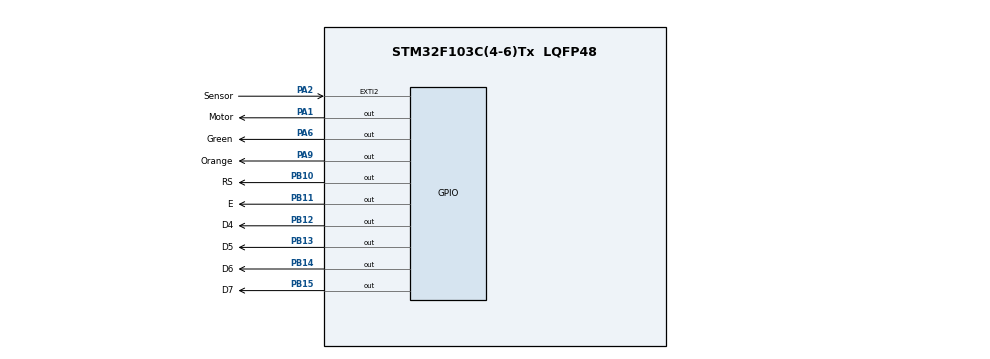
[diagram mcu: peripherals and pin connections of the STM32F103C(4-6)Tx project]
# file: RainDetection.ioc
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Mcu.Family=STM32F1
Mcu.Name=STM32F103C(4-6)Tx
Mcu.Package=LQFP48
NVIC.EXTI2_IRQn=true\:0\:0\:false\:false\:true\:true\:true\:true
NVIC.PriorityGroup=NVIC_PRIORITYGROUP_4
PA1.GPIO_Label=Motor
PA1.Signal=GPIO_Output
PA2.GPIO_Label=Sensor
PA2.Signal=GPXTI2
PA6.GPIO_Label=Green
PA6.Signal=GPIO_Output
PA9.GPIO_Label=Orange
PA9.Signal=GPIO_Output
PB10.GPIO_Label=RS
PB10.Signal=GPIO_Output
PB11.GPIO_Label=E
PB11.Signal=GPIO_Output
PB12.GPIO_Label=D4
PB12.Signal=GPIO_Output
PB13.GPIO_Label=D5
PB13.Signal=GPIO_Output
PB14.GPIO_Label=D6
PB14.Signal=GPIO_Output
PB15.GPIO_Label=D7
PB15.Signal=GPIO_Output
PD0-OSC_IN.Mode=HSE-External-Oscillator
PD0-OSC_IN.Signal=RCC_OSC_IN
PD1-OSC_OUT.Mode=HSE-External-Oscillator
PD1-OSC_OUT.Signal=RCC_OSC_OUT
ProjectManager.HeapSize=0x200
ProjectManager.StackSize=0x400
ProjectManager.TargetToolchain=MDK-ARM V5.32
RCC.APB1Freq_Value=8000000
RCC.APB2Freq_Value=8000000
VP_SYS_VS_ND.Mode=No_Debug
VP_TIM2_VS_ClockSourceINT.Mode=Internal
board=custom

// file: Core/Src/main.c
/* USER CODE BEGIN Header */
/**
  ******************************************************************************
  * @file           : main.c
  * @brief          : Main program body
  ******************************************************************************
  * @attention
  *
  * Copyright (c) 2023 STMicroelectronics.
  * All rights reserved.
  *
  * This software is licensed under terms that can be found in the LICENSE file
  * in the root directory of this software component.
  * If no LICENSE file comes with this software, it is provided AS-IS.
  *
  ******************************************************************************
  */
/* USER CODE END Header */
#include "main.h"
#include "stdio.h"
#include "lcd_txt.h"

TIM_HandleTypeDef htim2;

void SystemClock_Config(void);
static void MX_GPIO_Init(void);
static void MX_TIM2_Init(void);

int main(void)
{

  /* MCU Configuration--------------------------------------------------------*/

  /* Reset of all peripherals, Initializes the Flash interface and the Systick. */
  HAL_Init();

  /* Configure the system clock */
  SystemClock_Config();

  /* Initialize all configured peripherals */
  MX_GPIO_Init();
  MX_TIM2_Init();
  /* USER CODE BEGIN 2 */
	lcd_init();
  /* USER CODE END 2 */

  /* Infinite loop */
  /* USER CODE BEGIN WHILE */
  while (1)
  {

		if (HAL_GPIO_ReadPin(GPIOA, GPIO_PIN_2)) // if the pin is HIGH
		{
			HAL_GPIO_WritePin(GPIOA, GPIO_PIN_1, 0);
			lcd_puts(0, 0, (int8_t*)"RAIN DETECTED: Y");
			lcd_puts(1, 0, (int8_t*)"ROOF CLOSING:  Y");
			//HAL_GPIO_WritePin(GPIOA, GPIO_PIN_9, 1);
			//HAL_GPIO_WritePin(GPIOA, GPIO_PIN_6, GPIO_PIN_RESET);
		}
		else if(!HAL_GPIO_ReadPin(GPIOA, GPIO_PIN_2)){
			HAL_GPIO_WritePin(GPIOA, GPIO_PIN_1, 1);
			lcd_puts(0, 0, (int8_t*)"RAIN DETECTED: N");
			lcd_puts(1, 0, (int8_t*)"ROOF CLOSING:  N");
			//HAL_GPIO_WritePin(GPIOA, GPIO_PIN_6, 1);
			// HAL_GPIO_WritePin(GPIOA, GPIO_PIN_9, GPIO_PIN_RESET);

		}

    /* USER CODE END WHILE */

  }
}

void SystemClock_Config(void)
{
  RCC_OscInitTypeDef RCC_OscInitStruct = {0};
  RCC_ClkInitTypeDef RCC_ClkInitStruct = {0};

  /** Initializes the RCC Oscillators according to the specified parameters
  * in the RCC_OscInitTypeDef structure.
  */
  RCC_OscInitStruct.OscillatorType = RCC_OSCILLATORTYPE_HSI;
  RCC_OscInitStruct.HSIState = RCC_HSI_ON;
  RCC_OscInitStruct.HSICalibrationValue = RCC_HSICALIBRATION_DEFAULT;
  RCC_OscInitStruct.PLL.PLLState = RCC_PLL_NONE;
  if (HAL_RCC_OscConfig(&RCC_OscInitStruct) != HAL_OK)
  {
    Error_Handler();
  }

  /** Initializes the CPU, AHB and APB buses clocks
  */
  RCC_ClkInitStruct.ClockType = RCC_CLOCKTYPE_HCLK|RCC_CLOCKTYPE_SYSCLK
                              |RCC_CLOCKTYPE_PCLK1|RCC_CLOCKTYPE_PCLK2;
  RCC_ClkInitStruct.SYSCLKSource = RCC_SYSCLKSOURCE_HSI;
  RCC_ClkInitStruct.AHBCLKDivider = RCC_SYSCLK_DIV1;
  RCC_ClkInitStruct.APB1CLKDivider = RCC_HCLK_DIV1;
  RCC_ClkInitStruct.APB2CLKDivider = RCC_HCLK_DIV1;

  if (HAL_RCC_ClockConfig(&RCC_ClkInitStruct, FLASH_LATENCY_0) != HAL_OK)
  {
    Error_Handler();
  }
}

static void MX_TIM2_Init(void)
{

  TIM_ClockConfigTypeDef sClockSourceConfig = {0};
  TIM_MasterConfigTypeDef sMasterConfig = {0};

  htim2.Instance = TIM2;
  htim2.Init.Prescaler = 0;
  htim2.Init.CounterMode = TIM_COUNTERMODE_UP;
  htim2.Init.Period = 65535;
  htim2.Init.ClockDivision = TIM_CLOCKDIVISION_DIV1;
  htim2.Init.AutoReloadPreload = TIM_AUTORELOAD_PRELOAD_DISABLE;
  if (HAL_TIM_Base_Init(&htim2) != HAL_OK)
  {
    Error_Handler();
  }
  sClockSourceConfig.ClockSource = TIM_CLOCKSOURCE_INTERNAL;
  if (HAL_TIM_ConfigClockSource(&htim2, &sClockSourceConfig) != HAL_OK)
  {
    Error_Handler();
  }
  sMasterConfig.MasterOutputTrigger = TIM_TRGO_RESET;
  sMasterConfig.MasterSlaveMode = TIM_MASTERSLAVEMODE_DISABLE;
  if (HAL_TIMEx_MasterConfigSynchronization(&htim2, &sMasterConfig) != HAL_OK)
  {
    Error_Handler();
  }

}

static void MX_GPIO_Init(void)
{
  GPIO_InitTypeDef GPIO_InitStruct = {0};

  /* GPIO Ports Clock Enable */
  __HAL_RCC_GPIOD_CLK_ENABLE();
  __HAL_RCC_GPIOA_CLK_ENABLE();
  __HAL_RCC_GPIOB_CLK_ENABLE();

  /*Configure GPIO pin Output Level */
  HAL_GPIO_WritePin(GPIOA, Motor_Pin|Green_Pin|Orange_Pin, GPIO_PIN_RESET);

  /*Configure GPIO pin Output Level */
  HAL_GPIO_WritePin(GPIOB, RS_Pin|E_Pin|D4_Pin|D5_Pin
                          |D6_Pin|D7_Pin, GPIO_PIN_RESET);

  /*Configure GPIO pins : Motor_Pin Green_Pin Orange_Pin */
  GPIO_InitStruct.Pin = Motor_Pin|Green_Pin|Orange_Pin;
  GPIO_InitStruct.Mode = GPIO_MODE_OUTPUT_PP;
  GPIO_InitStruct.Pull = GPIO_NOPULL;
  GPIO_InitStruct.Speed = GPIO_SPEED_FREQ_LOW;
  HAL_GPIO_Init(GPIOA, &GPIO_InitStruct);

  /*Configure GPIO pin : Sensor_Pin */
  GPIO_InitStruct.Pin = Sensor_Pin;
  GPIO_InitStruct.Mode = GPIO_MODE_IT_RISING;
  GPIO_InitStruct.Pull = GPIO_NOPULL;
  HAL_GPIO_Init(Sensor_GPIO_Port, &GPIO_InitStruct);

  /*Configure GPIO pins : RS_Pin E_Pin D4_Pin D5_Pin
                           D6_Pin D7_Pin */
  GPIO_InitStruct.Pin = RS_Pin|E_Pin|D4_Pin|D5_Pin
                          |D6_Pin|D7_Pin;
  GPIO_InitStruct.Mode = GPIO_MODE_OUTPUT_PP;
  GPIO_InitStruct.Pull = GPIO_NOPULL;
  GPIO_InitStruct.Speed = GPIO_SPEED_FREQ_LOW;
  HAL_GPIO_Init(GPIOB, &GPIO_InitStruct);

  /* EXTI interrupt init*/
  HAL_NVIC_SetPriority(EXTI2_IRQn, 0, 0);
  HAL_NVIC_EnableIRQ(EXTI2_IRQn);

}

/* USER CODE BEGIN 4 */
void HAL_GPIO_EXTI_Callback(uint16_t GPIO_Pin)
{
  if (GPIO_Pin == GPIO_PIN_2)
  {
    HAL_GPIO_TogglePin(GPIOA, GPIO_PIN_9);
  };

}

/* USER CODE END 4 */

void Error_Handler(void)
{
  __disable_irq();
  while (1)
  {
  }
}
